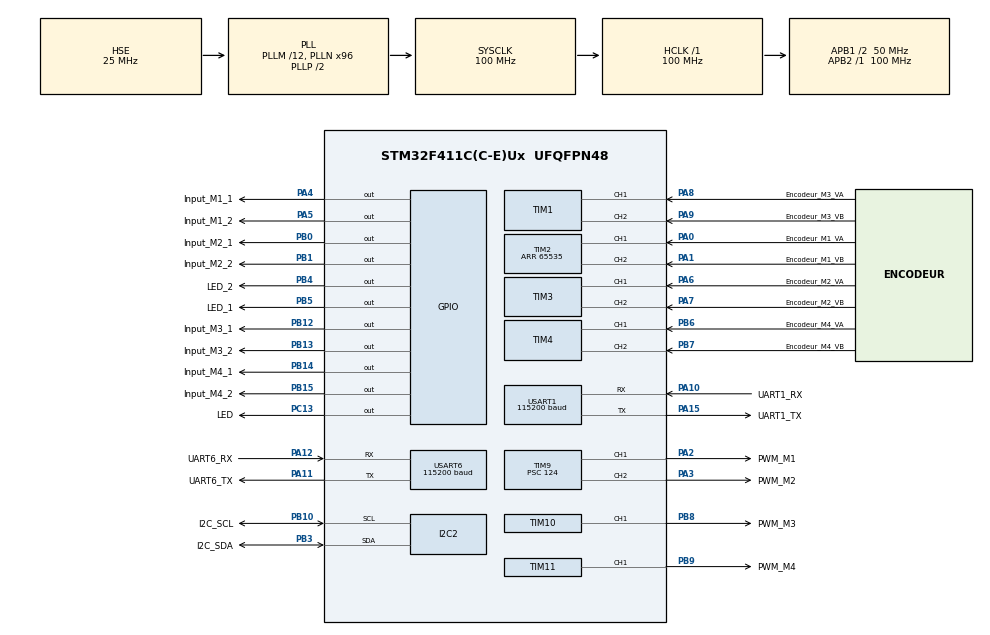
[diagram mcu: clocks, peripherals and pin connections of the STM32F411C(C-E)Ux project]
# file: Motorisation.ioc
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I2C2.I2C_Mode=I2C_Fast
Mcu.Family=STM32F4
Mcu.Name=STM32F411C(C-E)Ux
Mcu.Package=UFQFPN48
NVIC.I2C2_ER_IRQn=true\:0\:0\:false\:false\:true\:true\:true\:true
NVIC.I2C2_EV_IRQn=true\:0\:0\:false\:false\:true\:true\:true\:true
NVIC.PriorityGroup=NVIC_PRIORITYGROUP_3
NVIC.TIM5_IRQn=true\:2\:1\:true\:false\:true\:true\:true\:true
NVIC.USART1_IRQn=true\:1\:0\:true\:false\:true\:true\:true\:true
NVIC.USART6_IRQn=true\:1\:0\:true\:false\:true\:true\:true\:true
PA0-WKUP.GPIO_Label=Encodeur_M1_VA
PA0-WKUP.Signal=S_TIM2_CH1_ETR
PA1.GPIO_Label=Encodeur_M1_VB
PA1.Signal=S_TIM2_CH2
PA10.GPIO_Label=UART1_RX
PA10.Mode=Asynchronous
PA10.Signal=USART1_RX
PA11.GPIO_Label=UART6_TX
PA11.Mode=Asynchronous
PA11.Signal=USART6_TX
PA12.GPIO_Label=UART6_RX
PA12.Mode=Asynchronous
PA12.Signal=USART6_RX
PA15.GPIO_Label=UART1_TX
PA15.Mode=Asynchronous
PA15.Signal=USART1_TX
PA2.GPIO_Label=PWM_M1
PA2.Signal=S_TIM9_CH1
PA3.GPIO_Label=PWM_M2
PA3.Signal=S_TIM9_CH2
PA4.GPIO_Label=Input_M1_1
PA4.Signal=GPIO_Output
PA5.GPIO_Label=Input_M1_2
PA5.Signal=GPIO_Output
PA6.GPIO_Label=Encodeur_M2_VA
PA6.Signal=S_TIM3_CH1
PA7.GPIO_Label=Encodeur_M2_VB
PA7.Signal=S_TIM3_CH2
PA8.GPIO_Label=Encodeur_M3_VA
PA8.Signal=S_TIM1_CH1
PA9.GPIO_Label=Encodeur_M3_VB
PA9.Signal=S_TIM1_CH2
PB0.GPIO_Label=Input_M2_1
PB0.Signal=GPIO_Output
PB1.GPIO_Label=Input_M2_2
PB1.Signal=GPIO_Output
PB10.GPIO_Label=I2C_SCL
PB10.GPIO_Pu=GPIO_PULLUP
PB10.Mode=I2C
PB10.Signal=I2C2_SCL
PB12.GPIO_Label=Input_M3_1
PB12.Signal=GPIO_Output
PB13.GPIO_Label=Input_M3_2
PB13.Signal=GPIO_Output
PB14.GPIO_Label=Input_M4_1
PB14.Signal=GPIO_Output
PB15.GPIO_Label=Input_M4_2
PB15.Signal=GPIO_Output
PB3.GPIO_Label=I2C_SDA
PB3.GPIO_Mode=GPIO_MODE_AF_OD
PB3.GPIO_Pu=GPIO_PULLUP
PB3.Mode=I2C
PB3.Signal=I2C2_SDA
PB4.GPIO_Label=LED_2
PB4.GPIO_PuPd=GPIO_PULLDOWN
PB4.Signal=GPIO_Output
PB5.GPIO_Label=LED_1
PB5.GPIO_PuPd=GPIO_PULLDOWN
PB5.Signal=GPIO_Output
PB6.GPIO_Label=Encodeur_M4_VA
PB6.Signal=S_TIM4_CH1
PB7.GPIO_Label=Encodeur_M4_VB
PB7.Signal=S_TIM4_CH2
PB8.GPIO_Label=PWM_M3
PB8.Signal=S_TIM10_CH1
PB9.GPIO_Label=PWM_M4
PB9.Signal=S_TIM11_CH1
PC13-ANTI_TAMP.GPIO_Label=LED
PC13-ANTI_TAMP.Signal=GPIO_Output
PH0\ -\ OSC_IN.Mode=HSE-External-Oscillator
PH0\ -\ OSC_IN.Signal=RCC_OSC_IN
PH1\ -\ OSC_OUT.Mode=HSE-External-Oscillator
PH1\ -\ OSC_OUT.Signal=RCC_OSC_OUT
ProjectManager.HeapSize=0x200
ProjectManager.StackSize=0x400
ProjectManager.TargetToolchain=STM32CubeIDE
RCC.48MHZClocksFreq_Value=50000000
RCC.AHBFreq_Value=100000000
RCC.APB1CLKDivider=RCC_HCLK_DIV2
RCC.APB1Freq_Value=50000000
RCC.APB1TimFreq_Value=100000000
RCC.APB2Freq_Value=100000000
RCC.APB2TimFreq_Value=100000000
RCC.CortexFreq_Value=100000000
RCC.HCLKFreq_Value=100000000
RCC.HSE_VALUE=25000000
RCC.HSI_VALUE=16000000
RCC.LSE_VALUE=32768
RCC.PLLM=12
RCC.PLLN=96
RCC.PLLSourceVirtual=RCC_PLLSOURCE_HSE
RCC.SYSCLKFreq_VALUE=100000000
RCC.SYSCLKSource=RCC_SYSCLKSOURCE_PLLCLK
RCC.VCOOutputFreq_Value=200000000
SH.S_TIM10_CH1.0=TIM10_CH1,PWM Generation1 CH1
SH.S_TIM11_CH1.0=TIM11_CH1,PWM Generation1 CH1
SH.S_TIM1_CH1.0=TIM1_CH1,Encoder_Interface
SH.S_TIM1_CH2.0=TIM1_CH2,Encoder_Interface
SH.S_TIM2_CH1_ETR.0=TIM2_CH1,Encoder_Interface
SH.S_TIM2_CH2.0=TIM2_CH2,Encoder_Interface
SH.S_TIM3_CH1.0=TIM3_CH1,Encoder_Interface
SH.S_TIM3_CH2.0=TIM3_CH2,Encoder_Interface
SH.S_TIM4_CH1.0=TIM4_CH1,Encoder_Interface
SH.S_TIM4_CH2.0=TIM4_CH2,Encoder_Interface
SH.S_TIM9_CH1.0=TIM9_CH1,PWM Generation1 CH1
SH.S_TIM9_CH2.0=TIM9_CH2,PWM Generation2 CH2
TIM1.AutoReloadPreload=TIM_AUTORELOAD_PRELOAD_DISABLE
TIM1.EncoderMode=TIM_ENCODERMODE_TI12
TIM1.IC1Polarity=TIM_ICPOLARITY_FALLING
TIM10.Channel=TIM_CHANNEL_1
TIM10.Period=255
TIM10.Prescaler=124
TIM11.Channel=TIM_CHANNEL_1
TIM11.Period=255
TIM11.Prescaler=124
TIM2.AutoReloadPreload=TIM_AUTORELOAD_PRELOAD_DISABLE
TIM2.EncoderMode=TIM_ENCODERMODE_TI12
TIM2.IC1Polarity=TIM_ICPOLARITY_FALLING
TIM2.Period=65535
TIM3.AutoReloadPreload=TIM_AUTORELOAD_PRELOAD_DISABLE
TIM3.EncoderMode=TIM_ENCODERMODE_TI12
TIM3.IC1Polarity=TIM_ICPOLARITY_FALLING
TIM4.AutoReloadPreload=TIM_AUTORELOAD_PRELOAD_DISABLE
TIM4.EncoderMode=TIM_ENCODERMODE_TI12
TIM4.IC1Polarity=TIM_ICPOLARITY_FALLING
TIM5.AutoReloadPreload=TIM_AUTORELOAD_PRELOAD_DISABLE
TIM5.Period=499
TIM5.Prescaler=999
TIM9.Channel-PWM\ Generation1\ CH1=TIM_CHANNEL_1
TIM9.Channel-PWM\ Generation2\ CH2=TIM_CHANNEL_2
TIM9.Period=255
TIM9.Prescaler=124
USART1.BaudRate=115200
USART1.Mode=MODE_TX_RX
USART1.OverSampling=UART_OVERSAMPLING_8
USART1.VirtualMode=VM_ASYNC
USART6.BaudRate=115200
USART6.Mode=MODE_TX_RX
USART6.OverSampling=UART_OVERSAMPLING_8
USART6.VirtualMode=VM_ASYNC
VP_RTC_VS_RTC_Activate.Mode=RTC_Enabled
VP_TIM10_VS_ClockSourceINT.Mode=Enable_Timer
VP_TIM11_VS_ClockSourceINT.Mode=Enable_Timer
VP_TIM5_VS_ClockSourceINT.Mode=Internal
VP_TIM9_VS_ClockSourceINT.Mode=Internal
board=custom

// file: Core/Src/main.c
/* USER CODE BEGIN Header */
/**
  ******************************************************************************
  * @file           : main.c
  * @brief          : Main program body
  ******************************************************************************
  * @attention
  *
  * Copyright (c) 2024 STMicroelectronics.
  * All rights reserved.
  *
  * This software is licensed under terms that can be found in the LICENSE file
  * in the root directory of this software component.
  * If no LICENSE file comes with this software, it is provided AS-IS.
  *
  ******************************************************************************
  */
/* USER CODE END Header */
#include "main.h"

/* USER CODE BEGIN Includes */

#include "stdlib.h"
#include "mainprog.h"

/* USER CODE END Includes */

I2C_HandleTypeDef hi2c2;

RTC_HandleTypeDef hrtc;

TIM_HandleTypeDef htim1;
TIM_HandleTypeDef htim2;
TIM_HandleTypeDef htim3;
TIM_HandleTypeDef htim4;
TIM_HandleTypeDef htim5;
TIM_HandleTypeDef htim9;
TIM_HandleTypeDef htim10;
TIM_HandleTypeDef htim11;

UART_HandleTypeDef huart1;
UART_HandleTypeDef huart6;

void SystemClock_Config(void);
static void MX_GPIO_Init(void);
static void MX_I2C2_Init(void);
static void MX_TIM1_Init(void);
static void MX_TIM2_Init(void);
static void MX_TIM3_Init(void);
static void MX_TIM4_Init(void);
static void MX_TIM5_Init(void);
static void MX_TIM9_Init(void);
static void MX_TIM10_Init(void);
static void MX_TIM11_Init(void);
static void MX_USART1_UART_Init(void);
static void MX_USART6_UART_Init(void);
static void MX_RTC_Init(void);

int main(void)
{

  /* MCU Configuration--------------------------------------------------------*/

  /* Reset of all peripherals, Initializes the Flash interface and the Systick. */
  HAL_Init();

  /* Configure the system clock */
  SystemClock_Config();

  /* Initialize all configured peripherals */
  MX_GPIO_Init();
  MX_I2C2_Init();
  MX_TIM1_Init();
  MX_TIM2_Init();
  MX_TIM3_Init();
  MX_TIM4_Init();
  MX_TIM5_Init();
  MX_TIM9_Init();
  MX_TIM10_Init();
  MX_TIM11_Init();
  MX_USART1_UART_Init();
  MX_USART6_UART_Init();
  MX_RTC_Init();
  /* USER CODE BEGIN 2 */

  // ====================================== //
  // MAIN CODE
  // ====================================== //

  init();
  mainprog();

  // ====================================== //
  // ====================================== //

  /* USER CODE END 2 */

  /* Infinite loop */
  while (1)
  {

  }
}

void SystemClock_Config(void)
{
  RCC_OscInitTypeDef RCC_OscInitStruct = {0};
  RCC_ClkInitTypeDef RCC_ClkInitStruct = {0};

  /** Configure the main internal regulator output voltage
  */
  __HAL_RCC_PWR_CLK_ENABLE();
  __HAL_PWR_VOLTAGESCALING_CONFIG(PWR_REGULATOR_VOLTAGE_SCALE1);

  /** Initializes the RCC Oscillators according to the specified parameters
  * in the RCC_OscInitTypeDef structure.
  */
  RCC_OscInitStruct.OscillatorType = RCC_OSCILLATORTYPE_LSI|RCC_OSCILLATORTYPE_HSE;
  RCC_OscInitStruct.HSEState = RCC_HSE_ON;
  RCC_OscInitStruct.LSIState = RCC_LSI_ON;
  RCC_OscInitStruct.PLL.PLLState = RCC_PLL_ON;
  RCC_OscInitStruct.PLL.PLLSource = RCC_PLLSOURCE_HSE;
  RCC_OscInitStruct.PLL.PLLM = 12;
  RCC_OscInitStruct.PLL.PLLN = 96;
  RCC_OscInitStruct.PLL.PLLP = RCC_PLLP_DIV2;
  RCC_OscInitStruct.PLL.PLLQ = 4;
  if (HAL_RCC_OscConfig(&RCC_OscInitStruct) != HAL_OK)
  {
    Error_Handler();
  }

  /** Initializes the CPU, AHB and APB buses clocks
  */
  RCC_ClkInitStruct.ClockType = RCC_CLOCKTYPE_HCLK|RCC_CLOCKTYPE_SYSCLK
                              |RCC_CLOCKTYPE_PCLK1|RCC_CLOCKTYPE_PCLK2;
  RCC_ClkInitStruct.SYSCLKSource = RCC_SYSCLKSOURCE_PLLCLK;
  RCC_ClkInitStruct.AHBCLKDivider = RCC_SYSCLK_DIV1;
  RCC_ClkInitStruct.APB1CLKDivider = RCC_HCLK_DIV2;
  RCC_ClkInitStruct.APB2CLKDivider = RCC_HCLK_DIV1;

  if (HAL_RCC_ClockConfig(&RCC_ClkInitStruct, FLASH_LATENCY_3) != HAL_OK)
  {
    Error_Handler();
  }
}

static void MX_I2C2_Init(void)
{

  hi2c2.Instance = I2C2;
  hi2c2.Init.ClockSpeed = 400000;
  hi2c2.Init.DutyCycle = I2C_DUTYCYCLE_2;
  hi2c2.Init.OwnAddress1 = 0;
  hi2c2.Init.AddressingMode = I2C_ADDRESSINGMODE_7BIT;
  hi2c2.Init.DualAddressMode = I2C_DUALADDRESS_DISABLE;
  hi2c2.Init.OwnAddress2 = 0;
  hi2c2.Init.GeneralCallMode = I2C_GENERALCALL_DISABLE;
  hi2c2.Init.NoStretchMode = I2C_NOSTRETCH_DISABLE;
  if (HAL_I2C_Init(&hi2c2) != HAL_OK)
  {
    Error_Handler();
  }

}

static void MX_RTC_Init(void)
{

  /** Initialize RTC Only
  */
  hrtc.Instance = RTC;
  hrtc.Init.HourFormat = RTC_HOURFORMAT_24;
  hrtc.Init.AsynchPrediv = 127;
  hrtc.Init.SynchPrediv = 255;
  hrtc.Init.OutPut = RTC_OUTPUT_DISABLE;
  hrtc.Init.OutPutPolarity = RTC_OUTPUT_POLARITY_HIGH;
  hrtc.Init.OutPutType = RTC_OUTPUT_TYPE_OPENDRAIN;
  if (HAL_RTC_Init(&hrtc) != HAL_OK)
  {
    Error_Handler();
  }

}

static void MX_TIM1_Init(void)
{

  TIM_Encoder_InitTypeDef sConfig = {0};
  TIM_MasterConfigTypeDef sMasterConfig = {0};

  htim1.Instance = TIM1;
  htim1.Init.Prescaler = 0;
  htim1.Init.CounterMode = TIM_COUNTERMODE_UP;
  htim1.Init.Period = 65535;
  htim1.Init.ClockDivision = TIM_CLOCKDIVISION_DIV1;
  htim1.Init.RepetitionCounter = 0;
  htim1.Init.AutoReloadPreload = TIM_AUTORELOAD_PRELOAD_DISABLE;
  sConfig.EncoderMode = TIM_ENCODERMODE_TI12;
  sConfig.IC1Polarity = TIM_ICPOLARITY_FALLING;
  sConfig.IC1Selection = TIM_ICSELECTION_DIRECTTI;
  sConfig.IC1Prescaler = TIM_ICPSC_DIV1;
  sConfig.IC1Filter = 0;
  sConfig.IC2Polarity = TIM_ICPOLARITY_RISING;
  sConfig.IC2Selection = TIM_ICSELECTION_DIRECTTI;
  sConfig.IC2Prescaler = TIM_ICPSC_DIV1;
  sConfig.IC2Filter = 0;
  if (HAL_TIM_Encoder_Init(&htim1, &sConfig) != HAL_OK)
  {
    Error_Handler();
  }
  sMasterConfig.MasterOutputTrigger = TIM_TRGO_RESET;
  sMasterConfig.MasterSlaveMode = TIM_MASTERSLAVEMODE_DISABLE;
  if (HAL_TIMEx_MasterConfigSynchronization(&htim1, &sMasterConfig) != HAL_OK)
  {
    Error_Handler();
  }

}

static void MX_TIM2_Init(void)
{

  TIM_Encoder_InitTypeDef sConfig = {0};
  TIM_MasterConfigTypeDef sMasterConfig = {0};

  htim2.Instance = TIM2;
  htim2.Init.Prescaler = 0;
  htim2.Init.CounterMode = TIM_COUNTERMODE_UP;
  htim2.Init.Period = 65535;
  htim2.Init.ClockDivision = TIM_CLOCKDIVISION_DIV1;
  htim2.Init.AutoReloadPreload = TIM_AUTORELOAD_PRELOAD_DISABLE;
  sConfig.EncoderMode = TIM_ENCODERMODE_TI12;
  sConfig.IC1Polarity = TIM_ICPOLARITY_FALLING;
  sConfig.IC1Selection = TIM_ICSELECTION_DIRECTTI;
  sConfig.IC1Prescaler = TIM_ICPSC_DIV1;
  sConfig.IC1Filter = 0;
  sConfig.IC2Polarity = TIM_ICPOLARITY_RISING;
  sConfig.IC2Selection = TIM_ICSELECTION_DIRECTTI;
  sConfig.IC2Prescaler = TIM_ICPSC_DIV1;
  sConfig.IC2Filter = 0;
  if (HAL_TIM_Encoder_Init(&htim2, &sConfig) != HAL_OK)
  {
    Error_Handler();
  }
  sMasterConfig.MasterOutputTrigger = TIM_TRGO_RESET;
  sMasterConfig.MasterSlaveMode = TIM_MASTERSLAVEMODE_DISABLE;
  if (HAL_TIMEx_MasterConfigSynchronization(&htim2, &sMasterConfig) != HAL_OK)
  {
    Error_Handler();
  }

}

static void MX_TIM3_Init(void)
{

  TIM_Encoder_InitTypeDef sConfig = {0};
  TIM_MasterConfigTypeDef sMasterConfig = {0};

  htim3.Instance = TIM3;
  htim3.Init.Prescaler = 0;
  htim3.Init.CounterMode = TIM_COUNTERMODE_UP;
  htim3.Init.Period = 65535;
  htim3.Init.ClockDivision = TIM_CLOCKDIVISION_DIV1;
  htim3.Init.AutoReloadPreload = TIM_AUTORELOAD_PRELOAD_DISABLE;
  sConfig.EncoderMode = TIM_ENCODERMODE_TI12;
  sConfig.IC1Polarity = TIM_ICPOLARITY_FALLING;
  sConfig.IC1Selection = TIM_ICSELECTION_DIRECTTI;
  sConfig.IC1Prescaler = TIM_ICPSC_DIV1;
  sConfig.IC1Filter = 0;
  sConfig.IC2Polarity = TIM_ICPOLARITY_RISING;
  sConfig.IC2Selection = TIM_ICSELECTION_DIRECTTI;
  sConfig.IC2Prescaler = TIM_ICPSC_DIV1;
  sConfig.IC2Filter = 0;
  if (HAL_TIM_Encoder_Init(&htim3, &sConfig) != HAL_OK)
  {
    Error_Handler();
  }
  sMasterConfig.MasterOutputTrigger = TIM_TRGO_RESET;
  sMasterConfig.MasterSlaveMode = TIM_MASTERSLAVEMODE_DISABLE;
  if (HAL_TIMEx_MasterConfigSynchronization(&htim3, &sMasterConfig) != HAL_OK)
  {
    Error_Handler();
  }

}

static void MX_TIM4_Init(void)
{

  TIM_Encoder_InitTypeDef sConfig = {0};
  TIM_MasterConfigTypeDef sMasterConfig = {0};

  htim4.Instance = TIM4;
  htim4.Init.Prescaler = 0;
  htim4.Init.CounterMode = TIM_COUNTERMODE_UP;
  htim4.Init.Period = 65535;
  htim4.Init.ClockDivision = TIM_CLOCKDIVISION_DIV1;
  htim4.Init.AutoReloadPreload = TIM_AUTORELOAD_PRELOAD_DISABLE;
  sConfig.EncoderMode = TIM_ENCODERMODE_TI12;
  sConfig.IC1Polarity = TIM_ICPOLARITY_FALLING;
  sConfig.IC1Selection = TIM_ICSELECTION_DIRECTTI;
  sConfig.IC1Prescaler = TIM_ICPSC_DIV1;
  sConfig.IC1Filter = 0;
  sConfig.IC2Polarity = TIM_ICPOLARITY_RISING;
  sConfig.IC2Selection = TIM_ICSELECTION_DIRECTTI;
  sConfig.IC2Prescaler = TIM_ICPSC_DIV1;
  sConfig.IC2Filter = 0;
  if (HAL_TIM_Encoder_Init(&htim4, &sConfig) != HAL_OK)
  {
    Error_Handler();
  }
  sMasterConfig.MasterOutputTrigger = TIM_TRGO_RESET;
  sMasterConfig.MasterSlaveMode = TIM_MASTERSLAVEMODE_DISABLE;
  if (HAL_TIMEx_MasterConfigSynchronization(&htim4, &sMasterConfig) != HAL_OK)
  {
    Error_Handler();
  }

}

static void MX_TIM5_Init(void)
{

  TIM_ClockConfigTypeDef sClockSourceConfig = {0};
  TIM_MasterConfigTypeDef sMasterConfig = {0};

  htim5.Instance = TIM5;
  htim5.Init.Prescaler = 999;
  htim5.Init.CounterMode = TIM_COUNTERMODE_UP;
  htim5.Init.Period = 499;
  htim5.Init.ClockDivision = TIM_CLOCKDIVISION_DIV1;
  htim5.Init.AutoReloadPreload = TIM_AUTORELOAD_PRELOAD_DISABLE;
  if (HAL_TIM_Base_Init(&htim5) != HAL_OK)
  {
    Error_Handler();
  }
  sClockSourceConfig.ClockSource = TIM_CLOCKSOURCE_INTERNAL;
  if (HAL_TIM_ConfigClockSource(&htim5, &sClockSourceConfig) != HAL_OK)
  {
    Error_Handler();
  }
  sMasterConfig.MasterOutputTrigger = TIM_TRGO_RESET;
  sMasterConfig.MasterSlaveMode = TIM_MASTERSLAVEMODE_DISABLE;
  if (HAL_TIMEx_MasterConfigSynchronization(&htim5, &sMasterConfig) != HAL_OK)
  {
    Error_Handler();
  }

}

static void MX_TIM9_Init(void)
{

  TIM_ClockConfigTypeDef sClockSourceConfig = {0};
  TIM_OC_InitTypeDef sConfigOC = {0};

  htim9.Instance = TIM9;
  htim9.Init.Prescaler = 124;
  htim9.Init.CounterMode = TIM_COUNTERMODE_UP;
  htim9.Init.Period = 255;
  htim9.Init.ClockDivision = TIM_CLOCKDIVISION_DIV1;
  htim9.Init.AutoReloadPreload = TIM_AUTORELOAD_PRELOAD_DISABLE;
  if (HAL_TIM_Base_Init(&htim9) != HAL_OK)
  {
    Error_Handler();
  }
  sClockSourceConfig.ClockSource = TIM_CLOCKSOURCE_INTERNAL;
  if (HAL_TIM_ConfigClockSource(&htim9, &sClockSourceConfig) != HAL_OK)
  {
    Error_Handler();
  }
  if (HAL_TIM_PWM_Init(&htim9) != HAL_OK)
  {
    Error_Handler();
  }
  sConfigOC.OCMode = TIM_OCMODE_PWM1;
  sConfigOC.Pulse = 0;
  sConfigOC.OCPolarity = TIM_OCPOLARITY_HIGH;
  sConfigOC.OCFastMode = TIM_OCFAST_DISABLE;
  if (HAL_TIM_PWM_ConfigChannel(&htim9, &sConfigOC, TIM_CHANNEL_1) != HAL_OK)
  {
    Error_Handler();
  }
  if (HAL_TIM_PWM_ConfigChannel(&htim9, &sConfigOC, TIM_CHANNEL_2) != HAL_OK)
  {
    Error_Handler();
  }
  HAL_TIM_MspPostInit(&htim9);

}

static void MX_TIM10_Init(void)
{

  TIM_OC_InitTypeDef sConfigOC = {0};

  htim10.Instance = TIM10;
  htim10.Init.Prescaler = 124;
  htim10.Init.CounterMode = TIM_COUNTERMODE_UP;
  htim10.Init.Period = 255;
  htim10.Init.ClockDivision = TIM_CLOCKDIVISION_DIV1;
  htim10.Init.AutoReloadPreload = TIM_AUTORELOAD_PRELOAD_DISABLE;
  if (HAL_TIM_Base_Init(&htim10) != HAL_OK)
  {
    Error_Handler();
  }
  if (HAL_TIM_PWM_Init(&htim10) != HAL_OK)
  {
    Error_Handler();
  }
  sConfigOC.OCMode = TIM_OCMODE_PWM1;
  sConfigOC.Pulse = 0;
  sConfigOC.OCPolarity = TIM_OCPOLARITY_HIGH;
  sConfigOC.OCFastMode = TIM_OCFAST_DISABLE;
  if (HAL_TIM_PWM_ConfigChannel(&htim10, &sConfigOC, TIM_CHANNEL_1) != HAL_OK)
  {
    Error_Handler();
  }
  HAL_TIM_MspPostInit(&htim10);

}

static void MX_TIM11_Init(void)
{

  TIM_OC_InitTypeDef sConfigOC = {0};

  htim11.Instance = TIM11;
  htim11.Init.Prescaler = 124;
  htim11.Init.CounterMode = TIM_COUNTERMODE_UP;
  htim11.Init.Period = 255;
  htim11.Init.ClockDivision = TIM_CLOCKDIVISION_DIV1;
  htim11.Init.AutoReloadPreload = TIM_AUTORELOAD_PRELOAD_DISABLE;
  if (HAL_TIM_Base_Init(&htim11) != HAL_OK)
  {
    Error_Handler();
  }
  if (HAL_TIM_PWM_Init(&htim11) != HAL_OK)
  {
    Error_Handler();
  }
  sConfigOC.OCMode = TIM_OCMODE_PWM1;
  sConfigOC.Pulse = 0;
  sConfigOC.OCPolarity = TIM_OCPOLARITY_HIGH;
  sConfigOC.OCFastMode = TIM_OCFAST_DISABLE;
  if (HAL_TIM_PWM_ConfigChannel(&htim11, &sConfigOC, TIM_CHANNEL_1) != HAL_OK)
  {
    Error_Handler();
  }
  HAL_TIM_MspPostInit(&htim11);

}

static void MX_USART1_UART_Init(void)
{

  huart1.Instance = USART1;
  huart1.Init.BaudRate = 115200;
  huart1.Init.WordLength = UART_WORDLENGTH_8B;
  huart1.Init.StopBits = UART_STOPBITS_1;
  huart1.Init.Parity = UART_PARITY_NONE;
  huart1.Init.Mode = UART_MODE_TX_RX;
  huart1.Init.HwFlowCtl = UART_HWCONTROL_NONE;
  huart1.Init.OverSampling = UART_OVERSAMPLING_8;
  if (HAL_UART_Init(&huart1) != HAL_OK)
  {
    Error_Handler();
  }

}

static void MX_USART6_UART_Init(void)
{

  huart6.Instance = USART6;
  huart6.Init.BaudRate = 115200;
  huart6.Init.WordLength = UART_WORDLENGTH_8B;
  huart6.Init.StopBits = UART_STOPBITS_1;
  huart6.Init.Parity = UART_PARITY_NONE;
  huart6.Init.Mode = UART_MODE_TX_RX;
  huart6.Init.HwFlowCtl = UART_HWCONTROL_NONE;
  huart6.Init.OverSampling = UART_OVERSAMPLING_8;
  if (HAL_UART_Init(&huart6) != HAL_OK)
  {
    Error_Handler();
  }

}

static void MX_GPIO_Init(void)
{
  GPIO_InitTypeDef GPIO_InitStruct = {0};

  /* GPIO Ports Clock Enable */
  __HAL_RCC_GPIOC_CLK_ENABLE();
  __HAL_RCC_GPIOH_CLK_ENABLE();
  __HAL_RCC_GPIOA_CLK_ENABLE();
  __HAL_RCC_GPIOB_CLK_ENABLE();

  /*Configure GPIO pin Output Level */
  HAL_GPIO_WritePin(LED_GPIO_Port, LED_Pin, GPIO_PIN_RESET);

  /*Configure GPIO pin Output Level */
  HAL_GPIO_WritePin(GPIOA, Input_M1_1_Pin|Input_M1_2_Pin, GPIO_PIN_RESET);

  /*Configure GPIO pin Output Level */
  HAL_GPIO_WritePin(GPIOB, Input_M2_1_Pin|Input_M2_2_Pin|Input_M3_1_Pin|Input_M3_2_Pin
                          |Input_M4_1_Pin|Input_M4_2_Pin|LED_2_Pin|LED_1_Pin, GPIO_PIN_RESET);

  /*Configure GPIO pin : LED_Pin */
  GPIO_InitStruct.Pin = LED_Pin;
  GPIO_InitStruct.Mode = GPIO_MODE_OUTPUT_PP;
  GPIO_InitStruct.Pull = GPIO_NOPULL;
  GPIO_InitStruct.Speed = GPIO_SPEED_FREQ_LOW;
  HAL_GPIO_Init(LED_GPIO_Port, &GPIO_InitStruct);

  /*Configure GPIO pins : Input_M1_1_Pin Input_M1_2_Pin */
  GPIO_InitStruct.Pin = Input_M1_1_Pin|Input_M1_2_Pin;
  GPIO_InitStruct.Mode = GPIO_MODE_OUTPUT_PP;
  GPIO_InitStruct.Pull = GPIO_NOPULL;
  GPIO_InitStruct.Speed = GPIO_SPEED_FREQ_LOW;
  HAL_GPIO_Init(GPIOA, &GPIO_InitStruct);

  /*Configure GPIO pins : Input_M2_1_Pin Input_M2_2_Pin Input_M3_1_Pin Input_M3_2_Pin
                           Input_M4_1_Pin Input_M4_2_Pin */
  GPIO_InitStruct.Pin = Input_M2_1_Pin|Input_M2_2_Pin|Input_M3_1_Pin|Input_M3_2_Pin
                          |Input_M4_1_Pin|Input_M4_2_Pin;
  GPIO_InitStruct.Mode = GPIO_MODE_OUTPUT_PP;
  GPIO_InitStruct.Pull = GPIO_NOPULL;
  GPIO_InitStruct.Speed = GPIO_SPEED_FREQ_LOW;
  HAL_GPIO_Init(GPIOB, &GPIO_InitStruct);

  /*Configure GPIO pins : LED_2_Pin LED_1_Pin */
  GPIO_InitStruct.Pin = LED_2_Pin|LED_1_Pin;
  GPIO_InitStruct.Mode = GPIO_MODE_OUTPUT_PP;
  GPIO_InitStruct.Pull = GPIO_PULLDOWN;
  GPIO_InitStruct.Speed = GPIO_SPEED_FREQ_LOW;
  HAL_GPIO_Init(GPIOB, &GPIO_InitStruct);

}

void Error_Handler(void)
{
  __disable_irq();
  while (1)
  {
  }
}
